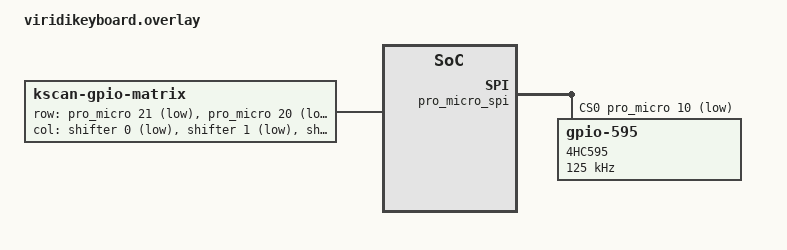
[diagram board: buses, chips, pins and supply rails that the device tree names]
&pro_micro_spi {
	status = "okay";
	cs-gpios = <&pro_micro 10 GPIO_ACTIVE_LOW>;
	shifter: 595@0 {
		compatible = "zmk,gpio-595";
		status = "okay";
		gpio-controller;
		spi-max-frequency = <125000>;
		reg = <0>;
		label = "4HC595";
		#gpio-cells = <2>;
		ngpios = <24>;
	};
};

/ {
	chosen {
		zephyr,display = &oled;
		zmk,kscan = &kscan0;
	};


	kscan0: kscan_0 {
		compatible = "zmk,kscan-gpio-matrix";
		label = "KSCAN";

		diode-direction = "col2row";
		row-gpios
			= <&pro_micro 21  (GPIO_ACTIVE_LOW)>
			, <&pro_micro 20  (GPIO_ACTIVE_LOW)>
			, <&pro_micro 19  (GPIO_ACTIVE_LOW)>
			, <&pro_micro 18  (GPIO_ACTIVE_LOW)>
			, <&pro_micro 5   (GPIO_ACTIVE_LOW)>
			, <&pro_micro 6   (GPIO_ACTIVE_LOW)>
			;
		col-gpios
			= <&shifter 0  GPIO_ACTIVE_LOW>
			, <&shifter 1  GPIO_ACTIVE_LOW>
			, <&shifter 2  GPIO_ACTIVE_LOW>
			, <&shifter 3  GPIO_ACTIVE_LOW>
            , <&shifter 4  GPIO_ACTIVE_LOW>
			, <&shifter 5  GPIO_ACTIVE_LOW>
			, <&shifter 6  GPIO_ACTIVE_LOW>
			, <&shifter 7  GPIO_ACTIVE_LOW>
            , <&shifter 8  GPIO_ACTIVE_LOW>
			, <&shifter 9  GPIO_ACTIVE_LOW>
            , <&shifter 10 GPIO_ACTIVE_LOW>
		    , <&shifter 11 GPIO_ACTIVE_LOW>
			, <&shifter 12 GPIO_ACTIVE_LOW>
			, <&shifter 13 GPIO_ACTIVE_LOW>
            , <&shifter 14 GPIO_ACTIVE_LOW>
			, <&shifter 15 GPIO_ACTIVE_LOW>
			, <&shifter 16 GPIO_ACTIVE_LOW>
			, <&shifter 17 GPIO_ACTIVE_LOW>
            , <&shifter 18 GPIO_ACTIVE_LOW>
			, <&shifter 19 GPIO_ACTIVE_LOW>
            , <&shifter 20 GPIO_ACTIVE_LOW>
			;
	};
